# APM32F446 register map
File version: 1.0
CPU: CM4 r0p1, little endian, MPU, FPU, 4 interrupt priority bits
Registers are 32-bit, read-write, reset 0x0 unless marked. A register's access mark holds for its fields unless they carry their own. Offsets are from the block's base; [hi:lo] are bit positions; {n}, {i} and the like mark numbered series; 'fields as' and 'values as' point back to an identical list.

## PCM — Peripheral Clock management
Base 0x40065000
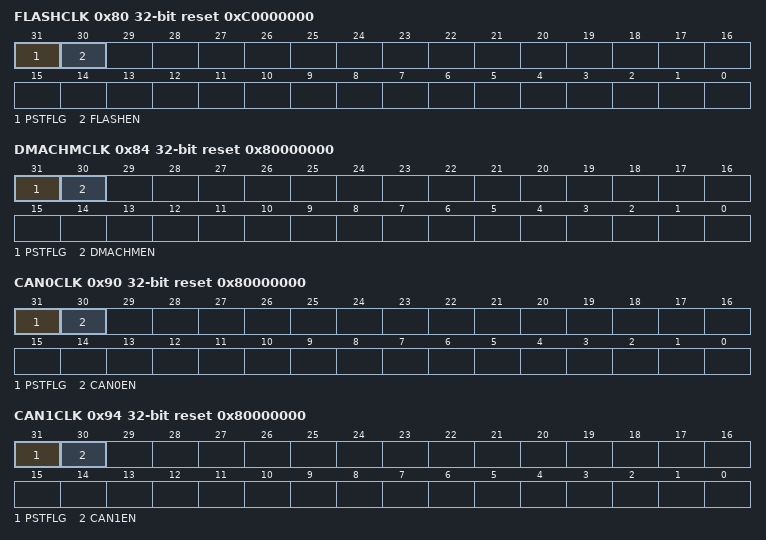
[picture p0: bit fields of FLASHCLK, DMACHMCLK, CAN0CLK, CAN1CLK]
0x80 FLASHCLK reset 0xC0000000 — FLASH Clock Register
  [31] PSTFLG ro — Peripheral Present Flag
    0=Peripheral is not present; 1=Peripheral is present
  [30] FLASHEN — Flash Clock Enable
    0=Clock disabled; 1=Clock enabled. The current clock selection and divider options are locked.
0x84 DMACHMCLK reset 0x80000000 — DMACHM Clock Register
  [31] PSTFLG ro — Peripheral Present Flag
    0=Peripheral is not present; 1=Peripheral is present
  [30] DMACHMEN — DMACHM Clock Enable
    values as FLASHCLK.FLASHEN
0x90 CAN0CLK reset 0x80000000 — CAN0 Clock Register
  [31] PSTFLG ro — Peripheral Present Flag
    0=Peripheral is not present; 1=Peripheral is present
  [30] CAN0EN — CAN0 Clock Enable
    values as FLASHCLK.FLASHEN
0x94 CAN1CLK reset 0x80000000 — CAN1 Clock Register
  [31] PSTFLG ro — Peripheral Present Flag
    0=Peripheral is not present; 1=Peripheral is present
  [30] CAN1EN — CAN1 Clock Enable
    values as FLASHCLK.FLASHEN
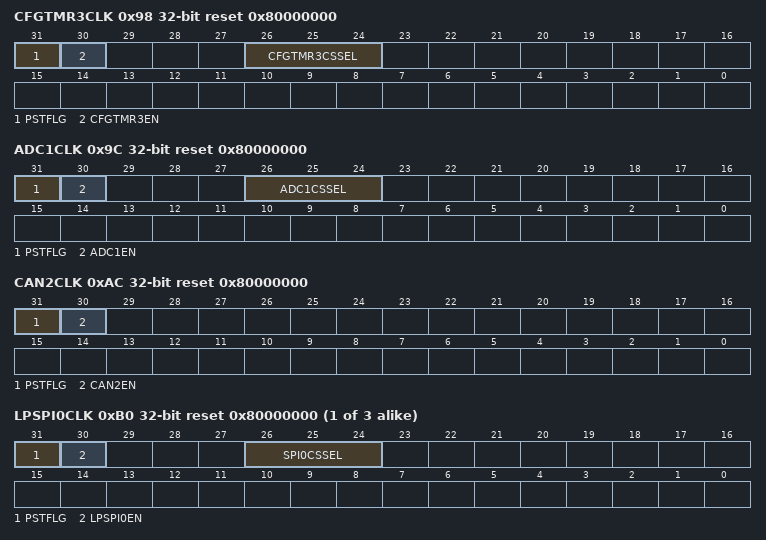
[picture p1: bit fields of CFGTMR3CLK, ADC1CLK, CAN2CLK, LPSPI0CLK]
0x98 CFGTMR3CLK reset 0x80000000 — CFGTMR3 Clock Register
  [31] PSTFLG ro — Peripheral Present Flag
    0=Peripheral is not present; 1=Peripheral is present
  [30] CFGTMR3EN — CFGTMR3 Clock Enable
    values as FLASHCLK.FLASHEN
  [26:24] CFGTMR3CSSEL — CFGTMR3 Clock Source Select
    0=Clock is off. An external clock can be enabled for this peripheral.; {v}=Clock option {v} (v=1..7)
0x9C ADC1CLK reset 0x80000000 — ADC1 Clock Register
  [31] PSTFLG ro — Peripheral Present Flag
    0=Peripheral is not present; 1=Peripheral is present
  [30] ADC1EN — ADC1 Clock Enable
    values as FLASHCLK.FLASHEN
  [26:24] ADC1CSSEL — ADC1 Clock Source Select
    0=Clock is off; {v}=Clock option {v} (v=1..7)
0xAC CAN2CLK reset 0x80000000 — CAN2 Clock Register
  [31] PSTFLG ro — Peripheral Present Flag
    0=Peripheral is not present; 1=Peripheral is present
  [30] CAN2EN — CAN2 Clock Enable
    values as FLASHCLK.FLASHEN
{0xB0+4i} LPSPI{i}CLK reset 0x80000000 (i=0..2) — LPSPI{i} Clock Register
  [31] PSTFLG ro — Peripheral Present Flag
    0=Peripheral is not present; 1=Peripheral is present
  [30] LPSPI{i}EN — LPSPI{i} Clock Enable
    values as FLASHCLK.FLASHEN
  [26:24] SPI{i}CSSEL — LPSPI{i} Clock Source Select
    0=Clock is off; {v}=Clock option {v} (v=1..7)
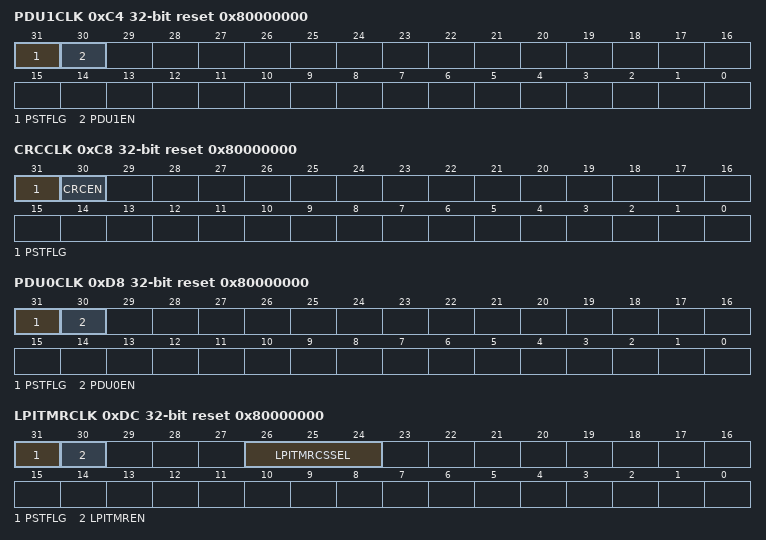
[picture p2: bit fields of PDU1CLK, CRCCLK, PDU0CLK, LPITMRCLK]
0xC4 PDU1CLK reset 0x80000000 — PDU1 Clock Register
  [31] PSTFLG ro — Peripheral Present Flag
    0=Peripheral is not present; 1=Peripheral is present
  [30] PDU1EN — PDU1 Clock Enable
    values as FLASHCLK.FLASHEN
0xC8 CRCCLK reset 0x80000000 — CRC Clock Register
  [31] PSTFLG ro — Peripheral Present Flag
    0=Peripheral is not present; 1=Peripheral is present
  [30] CRCEN — CRC Clock Enable
    values as FLASHCLK.FLASHEN
0xD8 PDU0CLK reset 0x80000000 — PDU0 Clock Register
  [31] PSTFLG ro — Peripheral Present Flag
    0=Peripheral is not present; 1=Peripheral is present
  [30] PDU0EN — PDU0 Clock Enable
    values as FLASHCLK.FLASHEN
0xDC LPITMRCLK reset 0x80000000 — PCC LPIT Clock Register
  [31] PSTFLG ro — Peripheral Present Flag
    0=Peripheral is not present; 1=Peripheral is present
  [30] LPITMREN — LPITMR Clock Enable
    values as FLASHCLK.FLASHEN
  [26:24] LPITMRCSSEL — LPITMR Clock Source Select
    0=Clock is off; {v}=Clock option {v} (v=1..7)
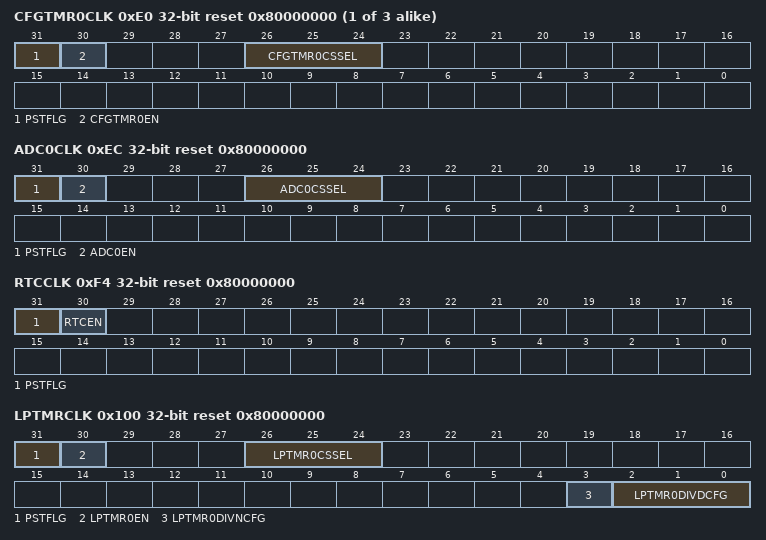
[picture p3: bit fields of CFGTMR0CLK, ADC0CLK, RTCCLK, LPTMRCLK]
{0xE0+4i} CFGTMR{i}CLK reset 0x80000000 (i=0..2) — CFGTMR{i} Clock Register
  [31] PSTFLG ro — Peripheral Present Flag
    0=Peripheral is not present; 1=Peripheral is present
  [30] CFGTMR{i}EN — CFGTMR{i} Clock Enable
    values as FLASHCLK.FLASHEN
  [26:24] CFGTMR{i}CSSEL — CFGTMR{i} Clock Source Select
    values as CFGTMR3CLK.CFGTMR3CSSEL
0xEC ADC0CLK reset 0x80000000 — ADC0 Clock Register
  [31] PSTFLG ro — Peripheral Present Flag
    0=Peripheral is not present; 1=Peripheral is present
  [30] ADC0EN — ADC0 Clock Enable
    values as FLASHCLK.FLASHEN
  [26:24] ADC0CSSEL — ADC0 Clock Source Select
    0=Clock is off; {v}=Clock option {v} (v=1..7)
0xF4 RTCCLK reset 0x80000000 — RTC Clock Register
  [31] PSTFLG ro — Peripheral Present Flag
    0=Peripheral is not present; 1=Peripheral is present
  [30] RTCEN — RTC Clock Enable
    values as FLASHCLK.FLASHEN
0x100 LPTMRCLK reset 0x80000000 — LPTMR Clock Register
  [31] PSTFLG ro — Peripheral Present Flag
    0=Peripheral is not present; 1=Peripheral is present
  [30] LPTMR0EN — LPTMR0 Clock Enable
    values as FLASHCLK.FLASHEN
  [26:24] LPTMR0CSSEL — LPTMR0 Clock Source Select
    0=Clock is off; {v}=Clock option {v} (v=1..7)
  [3] LPTMR0DIVNCFG — LPTMR0 Clock Divide Numerator Factor Configure
    0=Fractional value is 0; 1=Fractional value is 1
  [2:0] LPTMR0DIVDCFG — LPTMR0 Clock Divide Denominator Factor Configure
    {v}=Divide by {v+1} (v=0..7)
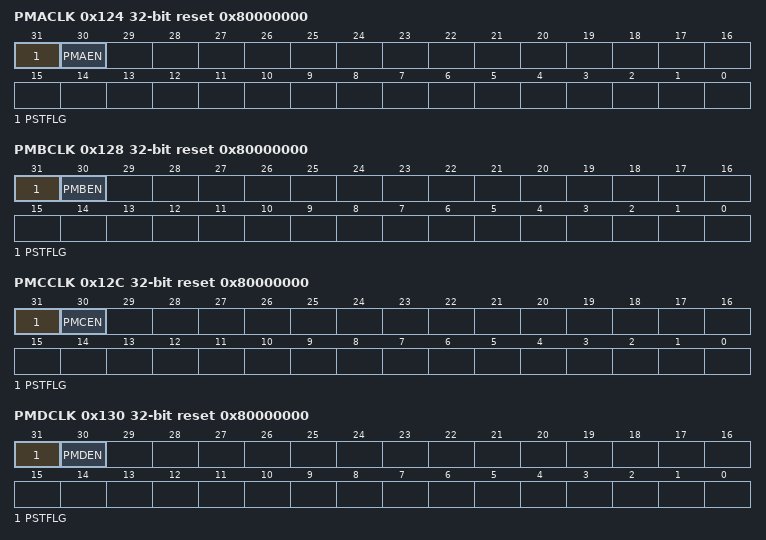
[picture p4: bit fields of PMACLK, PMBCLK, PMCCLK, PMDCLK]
0x124 PMACLK reset 0x80000000 — PMA Clock Register
  [31] PSTFLG ro — Peripheral Present Flag
    0=Peripheral is not present; 1=Peripheral is present
  [30] PMAEN — PMA Clock Enable
    values as FLASHCLK.FLASHEN
0x128 PMBCLK reset 0x80000000 — PMB Clock Register
  [31] PSTFLG ro — Peripheral Present Flag
    0=Peripheral is not present; 1=Peripheral is present
  [30] PMBEN — PMB Clock Enable
    values as FLASHCLK.FLASHEN
0x12C PMCCLK reset 0x80000000 — PMC Clock Register
  [31] PSTFLG ro — Peripheral Present Flag
    0=Peripheral is not present; 1=Peripheral is present
  [30] PMCEN — PMC Clock Enable
    values as FLASHCLK.FLASHEN
0x130 PMDCLK reset 0x80000000 — PMD Clock Register
  [31] PSTFLG ro — Peripheral Present Flag
    0=Peripheral is not present; 1=Peripheral is present
  [30] PMDEN — PMD Clock Enable
    values as FLASHCLK.FLASHEN
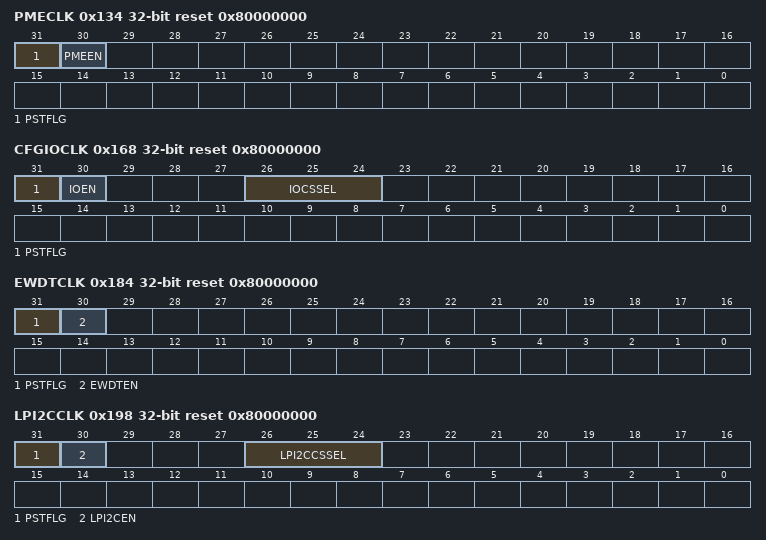
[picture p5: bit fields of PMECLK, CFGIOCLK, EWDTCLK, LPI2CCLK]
0x134 PMECLK reset 0x80000000 — PME Clock Register
  [31] PSTFLG ro — Peripheral Present Flag
    0=Peripheral is not present; 1=Peripheral is present
  [30] PMEEN — PME Clock Enable
    values as FLASHCLK.FLASHEN
0x168 CFGIOCLK reset 0x80000000 — Configurable IO Clock Register
  [31] PSTFLG ro — Peripheral Present Flag
    0=Peripheral is not present; 1=Peripheral is present
  [30] IOEN — IO Clock Enable
    values as FLASHCLK.FLASHEN
  [26:24] IOCSSEL — IO Clock Source Select
    0=Clock is off; {v}=Clock option {v} (v=1..7)
0x184 EWDTCLK reset 0x80000000 — EWDT Clock Register
  [31] PSTFLG ro — Peripheral Present Flag
    0=Peripheral is not present; 1=Peripheral is present
  [30] EWDTEN — EWDT Clock Enable
    values as FLASHCLK.FLASHEN
0x198 LPI2CCLK reset 0x80000000 — LPI2C0 Clock Register
  [31] PSTFLG ro — Peripheral Present Flag
    0=Peripheral is not present; 1=Peripheral is present
  [30] LPI2CEN — LPI2C Clock Enable
    values as FLASHCLK.FLASHEN
  [26:24] LPI2CCSSEL — LPI2C Clock Source Select
    0=Clock is off; {v}=Clock option {v} (v=1..7)
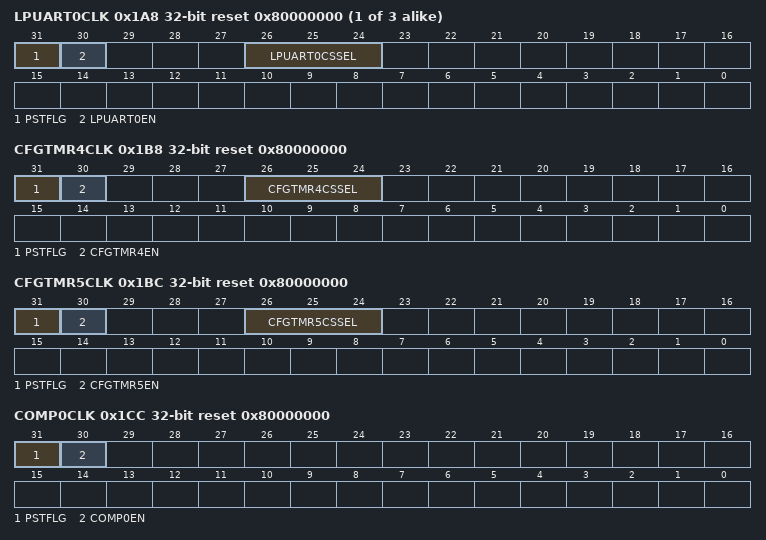
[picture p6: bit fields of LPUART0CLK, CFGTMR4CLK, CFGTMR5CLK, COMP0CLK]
{0x1A8+4i} LPUART{i}CLK reset 0x80000000 (i=0..2) — LPUART{i} Clock Register
  [31] PSTFLG ro — Peripheral Present Flag
    0=Peripheral is not present; 1=Peripheral is present
  [30] LPUART{i}EN — LPUART{i} Clock Enable
    values as FLASHCLK.FLASHEN
  [26:24] LPUART{i}CSSEL — LPUART{i} Clock Source Select
    0=Clock is off; {v}=Clock option {v} (v=1..7)
0x1B8 CFGTMR4CLK reset 0x80000000 — CFGTMR4 Clock Register
  [31] PSTFLG ro — Peripheral Present Flag
    0=Peripheral is not present; 1=Peripheral is present
  [30] CFGTMR4EN — CFGTMR4 Clock Enable
    values as FLASHCLK.FLASHEN
  [26:24] CFGTMR4CSSEL — CFGTMR4 Clock Source Select
    values as CFGTMR3CLK.CFGTMR3CSSEL
0x1BC CFGTMR5CLK reset 0x80000000 — CFGTMR5 Clock Register
  [31] PSTFLG ro — Peripheral Present Flag
    0=Peripheral is not present; 1=Peripheral is present
  [30] CFGTMR5EN — CFGTMR5 Clock Enable
    values as FLASHCLK.FLASHEN
  [26:24] CFGTMR5CSSEL — CFGTMR5 Clock Source Select
    values as CFGTMR3CLK.CFGTMR3CSSEL
0x1CC COMP0CLK reset 0x80000000 — COMP0 Clock Register
  [31] PSTFLG ro — Peripheral Present Flag
    0=Peripheral is not present; 1=Peripheral is present
  [30] COMP0EN — COMP0 Clock Enable
    values as FLASHCLK.FLASHEN
